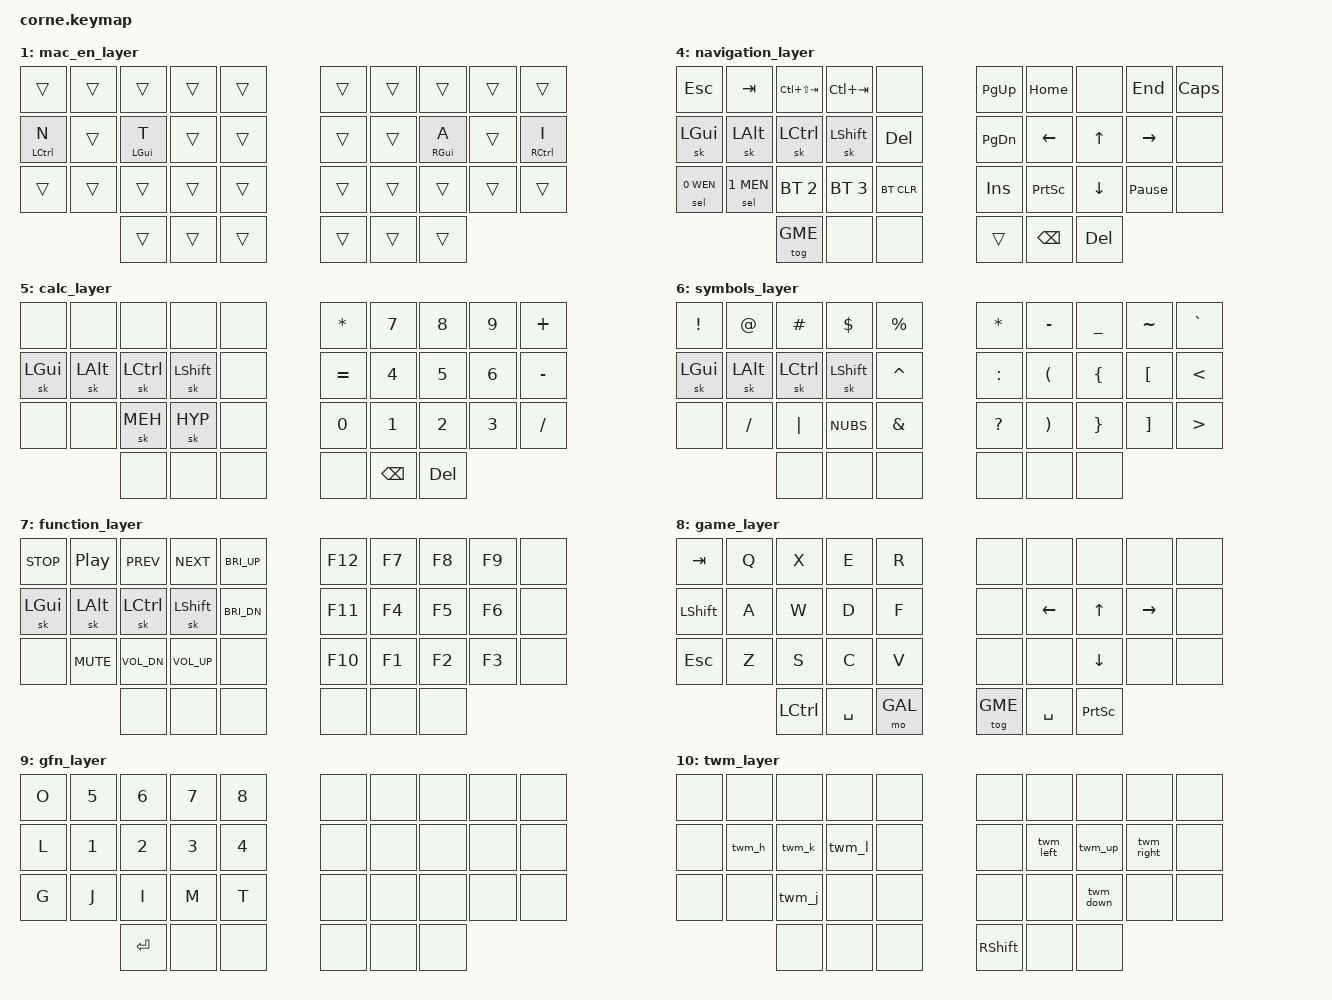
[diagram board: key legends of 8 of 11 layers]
/*
 * Copyright (c) 2020 The ZMK Contributors
 *
 * SPDX-License-Identifier: MIT
 */

#include <behaviors.dtsi>
#include <dt-bindings/zmk/keys.h>
#include <dt-bindings/zmk/bt.h>

#define PRV_TAB   &kp LC(LS(TAB)) 
#define NXT_TAB   &kp LC(TAB)

#define WIN_COPY  LC(C)
#define WIN_PASTE LC(V)
#define WIN_CUT   LC(X)
#define WIN_UNDO  LC(Z)
#define WIN_LANG  LG(SPACE)
#define MAC_COPY  LG(C)
#define MAC_PASTE LG(V)
#define MAC_CUT   LG(X)
#define MAC_UNDO  LG(Z)
#define MAC_LANG  LC(SPACE)

#define KEYS_L 0 1 2 3 4 10 11 12 13 14 20 21 22 23 24 // Left-hand keys
#define KEYS_R 5 6 7 8 9 15 16 17 18 19 25 26 27 28 29 // Right-hand keys
#define THUMBS 30 31 32 33 34 35                       // Thumb keys

// Win modifiers
#define HML(k1, k2, k3, k4)  &hml LGUI  k1 &hml LALT  k2 &hml LCTRL k3 &hml LSHFT k4
#define HMR(k1, k2, k3, k4)  &hmr RSHFT k1 &hmr RCTRL k2 &hmr RALT  k3 &hmr RGUI  k4
// Mac modifiers
#define HMLM(k1, k2, k3, k4) &hml LCTRL k1 &hml LALT  k2 &hml LGUI  k3 &hml LSHFT k4
#define HMRM(k1, k2, k3, k4) &hmr RSHFT k1 &hmr RGUI  k2 &hmr RALT  k3 &hmr RCTRL k4
// Hyper key
#define HYP LS(LC(LA(LGUI)))
// Meh key
#define MEH LS(LC(LALT))

#define COMBO_RU_HS  3  13
#define COMBO_RU_SH  6  16
#define COMBO_RU_YE  16 26
#define COMBO_RU_YO  7  17
#define COMBO_RU_EF  17 27

#define COMBO_COPY  12 22
#define COMBO_PASTE 13 23
#define COMBO_CUT   11 21
#define COMBO_UNDO  14 24
#define COMBO_LANG   2 12

#define WEN 0  // Win EN
#define MEN 1  // Mac EN
#define WRU 2  // Win RU
#define MRU 3  // Mac RU
#define NAV 4  // Navigation
#define CLC 5  // Calculator
#define SYM 6  // Symbols
#define FUN 7  // Functions
#define GME 8  // Game
#define GAL 9  // Game Alt
#define TWM 10 // Tiling Window Manager

#define COMBO_TIMEOUT 50
#define COMBO_IDLE 75
#define QUICK_TAP 150

// Macro-generator for russian letter key combos
#define RU_COMBO(NAME, KEYPOS, BIND) \
    combo_ru_##NAME { \
        timeout-ms = <COMBO_TIMEOUT>; \
        key-positions = <KEYPOS>; \
        bindings = <&kp BIND>; \
        layers = <WRU MRU>; \
	    require-prior-idle-ms = <COMBO_IDLE>; \
    };

// Macro-generator for basic OS combos
#define OS_COMBO(NAME, KEYPOS, WIN_BIND, MAC_BIND) \
    combo_##NAME##_win { \
        timeout-ms = <COMBO_TIMEOUT>; \
        key-positions = <KEYPOS>; \
        bindings = <&kp WIN_BIND>; \
        layers = <WEN WRU>; \
	    require-prior-idle-ms = <COMBO_IDLE>; \
    }; \
    combo_##NAME##_mac { \
        timeout-ms = <COMBO_TIMEOUT>; \
        key-positions = <KEYPOS>; \
        bindings = <&kp MAC_BIND>; \
        layers = <MEN MRU>; \
	    require-prior-idle-ms = <COMBO_IDLE>; \
    };

// Macro-generator for TWM layer
#define TWM_MORPH(NAME, KEY) \
    twm_##NAME: twm_##NAME { \
        compatible = "zmk,behavior-mod-morph"; \
        #binding-cells = <0>; \
        bindings = <&kp LS(LC(LA(KEY)))>, <&kp LS(LC(LA(LG(KEY))))>; \
        mods = <(MOD_RSFT)>; \
    };

&sk {
  quick-release;
};

/*            KEY POSITIONS
  ╭────────────────╮ ╭────────────────╮
  │ 0  1  2  3  4  │ │ 5  6  7  8  9  │
  │ 10 11 12 13 14 │ │ 15 16 17 18 19 │
  │ 20 21 22 23 24 │ │ 25 26 27 28 29 │
  ╰─────╮ 30 31 32 │ │ 33 34 35 ╭─────╯
        ╰──────────╯ ╰──────────╯ */

/ { chosen { zmk,matrix_transform = &five_column_transform; }; };

/ {
    combos {
        compatible = "zmk,combos";

		RU_COMBO(hs, COMBO_RU_HS, RBKT)  // Ъ
		RU_COMBO(sh, COMBO_RU_SH, O)     // Щ
		RU_COMBO(ye, COMBO_RU_YE, SQT)   // Э
		RU_COMBO(yo, COMBO_RU_YO, GRAVE) // Ё
		RU_COMBO(ef, COMBO_RU_EF, A)     // Ф

		OS_COMBO(copy,  COMBO_COPY,  WIN_COPY,  MAC_COPY)
		OS_COMBO(paste, COMBO_PASTE, WIN_PASTE, MAC_PASTE)
        OS_COMBO(cut,   COMBO_CUT,   WIN_CUT,   MAC_CUT)
        OS_COMBO(undo,  COMBO_UNDO,  WIN_UNDO,  MAC_UNDO)

        // Win - Change language
        combo_win_lang {
            timeout-ms = <COMBO_TIMEOUT>;
            key-positions = <COMBO_LANG>;
            bindings = <&lang WRU WIN_LANG>;
            layers = <WEN WRU>;
            require-prior-idle-ms = <COMBO_IDLE>;
        };

        // Mac - Change language
        combo_mac_lang {
            timeout-ms = <COMBO_TIMEOUT>;
            key-positions = <COMBO_LANG>;
            bindings = <&lang MRU MAC_LANG>;
            layers = <MEN MRU>;
            require-prior-idle-ms = <COMBO_IDLE>;
        };
    };  
};

 / {
  macros  {
    // Switch language and activate layer
    lang: lang {
      compatible = "zmk,behavior-macro-two-param";
      #binding-cells = <2>;
      wait-ms = <40>;
      tap-ms = <40>;
      bindings
        = <&macro_param_1to1>
        , <&macro_tap &tog MACRO_PLACEHOLDER>
        , <&macro_param_2to1>
        , <&macro_tap &kp MACRO_PLACEHOLDER>
        ;
    };
    // Select bluetooth profile and OS layer  
    sel: sel {
      compatible = "zmk,behavior-macro-two-param";
      #binding-cells = <2>;
      wait-ms = <40>;
      tap-ms = <40>;
      bindings
        = <&macro_param_1to1>
        , <&macro_tap &bt BT_SEL MACRO_PLACEHOLDER>
        , <&macro_param_2to1>
        , <&macro_tap &to MACRO_PLACEHOLDER>
        ;
    };
  };
};

/ {
    behaviors {
        hml: home_row_mod_left {
            compatible = "zmk,behavior-hold-tap";
            #binding-cells = <2>;
            flavor = "balanced";
            require-prior-idle-ms = <150>;
            tapping-term-ms = <280>;
            quick-tap-ms = <175>;
            bindings = <&kp>, <&kp>;
            hold-trigger-key-positions = <KEYS_R THUMBS>;
            hold-trigger-on-release;
        };
        hmr: home_row_mod_right {
            compatible = "zmk,behavior-hold-tap";
            #binding-cells = <2>;
            flavor = "balanced";
            require-prior-idle-ms = <150>;
            tapping-term-ms = <280>;
            quick-tap-ms = <175>;
            bindings = <&kp>, <&kp>;
            hold-trigger-key-positions = <KEYS_L THUMBS>;
            hold-trigger-on-release;
        };
        ltr: layer_tap_repeat {
            compatible = "zmk,behavior-hold-tap";
            #binding-cells = <2>;
            flavor = "tap-preferred";
            tapping-term-ms = <200>;
            bindings = <&mo>, <&key_repeat>;
			quick-tap-ms = <QUICK_TAP>;
        };

		TWM_MORPH(h, H)
		TWM_MORPH(j, J)
		TWM_MORPH(k, K)
		TWM_MORPH(l, L)
		TWM_MORPH(left, LEFT)
		TWM_MORPH(down, DOWN)
		TWM_MORPH(up, UP)
		TWM_MORPH(right, RIGHT)
    };
};

/ {        
  keymap {
    compatible = "zmk,keymap";

    //Gallium V2
    win_en_layer {
      bindings = <
        //   ╭──────────┬──────────┬──────────┬──────────┬──────────╮                         ╭──────────┬──────────┬──────────┬──────────┬──────────╮
        //   │  B       │  L       │  D       │  C       │  V       │                         │  J       │  Y       │  O       │  U       │  ,       │
                &kp B      &kp L     &lt TWM D   &kp C      &kp V                                &kp J      &kp Y     &lt TWM O   &kp U     &kp COMMA
        //   ├──────────┼──────────┼──────────┼──────────┼──────────┤                         ├──────────┼──────────┼──────────┼──────────┼──────────┤
        //   │  N       │  R       │  T       │  S       │  G       │                         │  P       │  H       │  A       │  E       │  I       │
                HML (N,    R,         T,         S)         &kp G                                &kp P      HMR(H,     A,         E,         I)
        //   ├──────────┼──────────┼──────────┼──────────┼──────────┤                         ├──────────┼──────────┼──────────┼──────────┼──────────┤
        //   │  X       │  Q       │  M       │  W       │  Z       │                         │  K       │  F       │  '       │  ;       │  .       │
                &kp X      &kp Q      &kp M      &kp W      &kp Z                                &kp K      &kp F      &kp SQT   &kp SEMI    &kp DOT
        //   ╰─────────────────────┴──────────┼──────────┼──────────┼──────────╮   ╭──────────┼──────────┼──────────┼──────────┴──────────┴──────────╯
        //                                    │  Repeat  │  SPACE   │  ENTER   │   │  SHIFT   │  BkSPC   │  DEL     │
                                              &ltr CLC 0  &lt NAV SPACE &kp ENTER  &kp LSHIFT &lt SYM BSPC &lt FUN DEL
        //                                    ╰──────────┴──────────┴──────────╯   ╰──────────┴──────────┴──────────╯
      >;
    };

    mac_en_layer {
      bindings = <
        //   ╭──────────┬──────────┬──────────┬──────────┬──────────╮                         ╭──────────┬──────────┬──────────┬──────────┬──────────╮
        //   │  B       │  L       │  D       │  C       │  V       │                         │  J       │  Y       │  O       │  U       │  ,       │
                &trans     &trans     &trans     &trans     &trans                               &trans     &trans     &trans     &trans     &trans
        //   ├──────────┼──────────┼──────────┼──────────┼──────────┤                         ├──────────┼──────────┼──────────┼──────────┼──────────┤
        //   │  N       │  R       │  T       │  S       │  G       │                         │  P       │  H       │  A       │  E       │  I       │
             &hml LCTRL N  &trans   &hml LGUI T  &trans     &trans                               &trans     &trans   &hmr RGUI A  &trans  &hmr RCTRL I
        //   ├──────────┼──────────┼──────────┼──────────┼──────────┤                         ├──────────┼──────────┼──────────┼──────────┼──────────┤
        //   │  X       │  Q       │  M       │  W       │  Z       │                         │  K       │  F       │  '       │  ;       │  .       │
                &trans     &trans     &trans     &trans     &trans                               &trans     &trans     &trans     &trans     &trans
        //   ╰──────────┴──────────┴──────────┼──────────┼──────────┼──────────╮   ╭──────────┼──────────┼──────────┼──────────┴──────────┴──────────╯
        //                                    │  Repeat  │  SPACE   │  ENTER   │   │  SHIFT   │  BkSPC   │  DEL     │
                                                 &trans     &trans     &trans         &trans     &trans     &trans
        //                                    ╰──────────┴──────────┴──────────╯   ╰──────────┴──────────┴──────────╯
      >;
    };

    win_ru_layer {
      bindings = <
        //   ╭──────────┬──────────┬──────────┬──────────┬──────────╮                         ╭──────────┬──────────┬──────────┬──────────┬──────────╮
        //   │  Ц       │  Й       │  К       │  Ь       │  Ч       │                         │  Ш       │  .       │  И       │  Я       │  Ю       │
                &kp W      &kp Q     &lt TWM R   &kp M      &kp X                                &kp I     &kp FSLH   &lt TWM B   &kp Z      &kp DOT
        //   ├──────────┼──────────┼──────────┼───(Ъ)────┼──────────┤                         ├──────────┼───(Щ)────┼───(Ё)────┼──────────┼──────────┤
        //   │  Т       │  Р       │  Н       │  В       │  М       │                         │  ,       │  С       │  А       │  О       │  Е       │
                HML (N,    H,         Y,         D)         &kp V                               &kp QMARK   HMR(C,     F,         J,         T)
        //   ├──────────┼──────────┼──────────┼──────────┼──────────┤                         ├──────────┼───(Э)────┼───(Ф)────┼──────────┼──────────┤
        //   │  Г       │  Л       │  П       │  Д       │  Б       │                         │  Ж       │  З       │  Ы       │  У       │  Х       │
                &kp U      &kp K      &kp G      &kp L     &kp COMMA                             &kp SEMI   &kp P      &kp S      &kp E      &kp LBKT
        //   ╰──────────┴──────────┴──────────┼──────────┼──────────┼──────────╮   ╭──────────┼──────────┼──────────┼──────────┴──────────┴──────────╯
        //                                    │  Repeat  │  SPACE   │  ENTER   │   │  SHIFT   │  BkSPC   │  DEL     │
                                                 &trans     &trans     &trans         &trans     &trans     &trans
        //                                    ╰──────────┴──────────┴──────────╯   ╰──────────┴──────────┴──────────╯
      >;
    };
    
    mac_ru_layer {
      bindings = <
        //   ╭──────────┬──────────┬──────────┬──────────┬──────────╮                         ╭──────────┬──────────┬──────────┬──────────┬──────────╮
        //   │  Ц       │  Й       │  К       │  Ь       │  Ч       │                         │  Ш       │  .       │  И       │  Я       │  Ю       │
                &kp W      &kp Q     &lt TWM R   &kp M      &kp X                                &kp I     &kp FSLH   &lt TWM B   &kp Z      &kp DOT
        //   ├──────────┼──────────┼──────────┼───(Ъ)────┼──────────┤                         ├──────────┼───(Щ)────┼───(Ё)────┼──────────┼──────────┤
        //   │  Т       │  Р       │  Н       │  В       │  М       │                         │  ,       │  С       │  А       │  О       │  Е       │
                HMLM (N,   H,         Y,         D)         &kp V                               &kp QMARK   HMRM(C,    F,         J,         T)
        //   ├──────────┼──────────┼──────────┼──────────┼──────────┤                         ├──────────┼───(Э)────┼───(Ф)────┼──────────┼──────────┤
        //   │  Г       │  Л       │  П       │  Д       │  Б       │                         │  Ж       │  З       │  Ы       │  У       │  Х       │
                &kp U      &kp K      &kp G      &kp L     &kp COMMA                             &kp SEMI   &kp P      &kp S      &kp E      &kp LBKT
        //   ╰──────────┴──────────┴──────────┼──────────┼──────────┼──────────╮   ╭──────────┼──────────┼──────────┼──────────┴──────────┴──────────╯
        //                                    │  Repeat  │  SPACE   │  ENTER   │   │  SHIFT   │  BkSPC   │  DEL     │
                                                 &trans     &trans     &trans         &trans     &trans     &trans
        //                                    ╰──────────┴──────────┴──────────╯   ╰──────────┴──────────┴──────────╯
      >;
    };

    navigation_layer {
      bindings = <
        //   ╭──────────┬──────────┬──────────┬──────────┬──────────╮                         ╭──────────┬──────────┬──────────┬──────────┬──────────╮
        //   │  ESC     │  TAB     │ PREV TAB │ NEXT TAB │          │                         │  PGUP    │  HOME    │          │  END     │  CAPS    │
                &kp ESC    &kp TAB   PRV_TAB    NXT_TAB     &none                               &kp PG_UP  &kp HOME    &none      &kp END   &kp CAPS
        //   ├──────────┼──────────┼──────────┼──────────┼──────────┤                         ├──────────┼──────────┼──────────┼──────────┼──────────┤
        //   │  GUI     │  ALT     │  CTRL    │  SHIFT   │  DEL     │                         │  PGDOWN  │  ←       │  ↑       │  →       │          │
               &sk LGUI   &sk LALT   &sk LCTRL  &sk LSHFT   &kp DEL                             &kp PG_DN  &kp LEFT    &kp UP    &kp RIGHT   &none
        //   ├──────────┼──────────┼──────────┼──────────┼──────────┤                         ├──────────┼──────────┼──────────┼──────────┼──────────┤
        //   │  BT 0    │  BT 1    │  BT 2    │  BT 3    │ BT CLEAR │                         │  INSERT  │  PTSCRN  │  ↓       │  PAUSE   │          │
           &sel 0 WEN &sel 1 MEN &bt BT_SEL 2 &bt BT_SEL 3 &bt BT_CLR                            &kp INS  &kp PSCRN &kp DOWN &kp PAUSE_BREAK &none
        //   ╰──────────┴──────────┴──────────┼──────────┼──────────┼──────────╮   ╭──────────┼──────────┼──────────┼──────────┴──────────┴──────────╯
        //                                    │  GAME    │  X       │          │   │  SHIFT   │  BkSPC   │  DEL     │
                                                &tog GME    &none     &none           &trans    &kp BSPC    &kp DEL
        //                                    ╰──────────┴──────────┴──────────╯   ╰──────────┴──────────┴──────────╯
      >;
    };                
 
    calc_layer {
      bindings = <
        //   ╭──────────┬──────────┬──────────┬──────────┬──────────╮                         ╭──────────┬──────────┬──────────┬──────────┬──────────╮
        //   │          │          │          │          │          │                         │  *       │  7       │  8       │  9       │  +       │
                &none      &none      &none      &none      &none                               &kp STAR    &kp N7     &kp N8     &kp N9    &kp PLUS
        //   ├──────────┼──────────┼──────────┼──────────┼──────────┤                         ├──────────┼──────────┼──────────┼──────────┼──────────┤
        //   │  GUI     │  ALT     │  CTRL    │  SHIFT   │          │                         │  =       │  4       │  5       │  6       │  -       │
               &sk LGUI   &sk LALT   &sk LCTRL  &sk LSHFT   &none                               &kp EQUAL   &kp N4     &kp N5     &kp N6    &kp MINUS
        //   ├──────────┼──────────┼──────────┼──────────┼──────────┤                         ├──────────┼──────────┼──────────┼──────────┼──────────┤
        //   │          │          │          │          │          │                         │  0       │  1       │  2       │  3       │  /       │
                &none      &none     &sk MEH    &sk HYP     &none                                &kp N0     &kp N1     &kp N2     &kp N3    &kp FSLH
        //   ╰──────────┴──────────┴──────────┼──────────┼──────────┼──────────╮   ╭──────────┼──────────┼──────────┼──────────┴──────────┴──────────╯
        //                                    │  X       │          │          │   │          │  BkSPC   │  DEL     │
                                                 &none      &none      &none          &none     &kp BSPC    &kp DEL
        //                                    ╰──────────┴──────────┴──────────╯   ╰──────────┴──────────┴──────────╯
      >;
    };

    symbols_layer {
      bindings = <
        //   ╭──────────┬──────────┬──────────┬──────────┬──────────╮                         ╭──────────┬──────────┬──────────┬──────────┬──────────╮
        //   │  !       │  @       │  #       │  $       │  %       │                         │  *       │  -       │  _       │  ~       │  `       │
               &kp EXCL    &kp AT    &kp HASH   &kp DLLR   &kp PRCNT                            &kp STAR  &kp MINUS   &kp UNDER  &kp TILDE  &kp GRAVE
        //   ├──────────┼──────────┼──────────┼──────────┼──────────┤                         ├──────────┼──────────┼──────────┼──────────┼──────────┤
        //   │  GUI     │  ALT     │  CTRL    │  SHIFT   │  ^       │                         │  :       │  (       │  {       │  [       │  <       │
               &sk LGUI   &sk LALT   &sk LCTRL  &sk LSHFT  &kp CARET                            &kp COLON  &kp LPAR   &kp LBRC   &kp LBKT    &kp LT
        //   ├──────────┼──────────┼──────────┼──────────┼──────────┤                         ├──────────┼──────────┼──────────┼──────────┼──────────┤
        //   │          │  /       │  |       │  \       │  &       │                         │  ?       │  )       │  }       │  ]       │  >       │
                &none     &kp FSLH   &kp PIPE   &kp NUBS   &kp AMPS                             &kp QMARK  &kp RPAR   &kp RBRC   &kp RBKT    &kp GT
        //   ╰──────────┴──────────┴──────────┼──────────┼──────────┼──────────╮   ╭──────────┼──────────┼──────────┼──────────┴──────────┴──────────╯
        //                                    │          │          │          │   │          │  X       │          │
                                                 &none      &none      &none          &none      &none      &none
        //                                    ╰──────────┴──────────┴──────────╯   ╰──────────┴──────────┴──────────╯
      >;
    };

    function_layer {
      bindings = <
        //   ╭──────────┬──────────┬──────────┬──────────┬──────────╮                         ╭──────────┬──────────┬──────────┬──────────┬──────────╮
        //   │  STOP    │  PLAY    │ PREVIOUS │  NEXT    │ BRIGHTUP │                         │  F12     │  F7      │  F8      │  F9      │          │
              &kp C_STOP  &kp C_PP  &kp C_PREV &kp C_NEXT &kp C_BRI_UP                           &kp F12    &kp F7     &kp F8     &kp F9     &none
        //   ├──────────┼──────────┼──────────┼──────────┼──────────┤                         ├──────────┼──────────┼──────────┼──────────┼──────────┤
        //   │  GUI     │  ALT     │  CTRL    │  SHIFT   │ BRIGHTDN │                         │  F11     │  F4      │  F5      │  F6      │          │
               &sk LGUI   &sk LALT   &sk LCTRL  &sk LSHFT &kp C_BRI_DN                           &kp F11    &kp F4     &kp F5     &kp F6     &none
        //   ├──────────┼──────────┼──────────┼──────────┼──────────┤                         ├──────────┼──────────┼──────────┼──────────┼──────────┤
        //   │          │  MUTE    │ VOL DWN  │  VOL UP  │          │                         │  F10     │  F1      │  F2      │  F3      │          │
                &none    &kp C_MUTE &kp C_VOL_DN &kp C_VOL_UP &none                              &kp F10    &kp F1     &kp F2     &kp F3     &none
        //   ╰──────────┴──────────┴──────────┼──────────┼──────────┼──────────╮   ╭──────────┼──────────┼──────────┼──────────┴──────────┴──────────╯
        //                                    │          │          │          │   │          │          │  X       │
                                                 &none      &none      &none          &none      &none      &none
        //                                    ╰──────────┴──────────┴──────────╯   ╰──────────┴──────────┴──────────╯
      >;
    };

    game_layer {
      bindings = <
        //   ╭──────────┬──────────┬──────────┬──────────┬──────────╮                         ╭──────────┬──────────┬──────────┬──────────┬──────────╮
        //   │  TAB     │  Q       │  X       │  E       │  R       │                         │          │          │          │          │          │
                &kp TAB    &kp Q      &kp X      &kp E      &kp R                                &none      &none      &none      &none      &none
        //   ├──────────┼──────────┼──────────┼──────────┼──────────┤                         ├──────────┼──────────┼──────────┼──────────┼──────────┤
        //   │  SHIFT   │  A       │  W       │  D       │  F       │                         │          │  ←       │  ↑       │  →       │          │
              &kp LSHIFT   &kp A      &kp W      &kp D      &kp F                                &none     &kp LEFT    &kp UP    &kp RIGHT   &none
        //   ├──────────┼──────────┼──────────┼──────────┼──────────┤                         ├──────────┼──────────┼──────────┼──────────┼──────────┤
        //   │  ESC     │  Z       │  S       │  C       │  V       │                         │          │          │  ↓       │          │          │
                &kp ESC    &kp Z      &kp S      &kp C      &kp V                                &none      &none     &kp DOWN    &none      &none
        //   ╰──────────┴──────────┴──────────┼──────────┼──────────┼──────────╮   ╭──────────┼──────────┼──────────┼──────────┴──────────┴──────────╯
        //                                    │  CTRL    │  SPACE   │ GAME FN  │   │  BASE    │  SPACE   │  PTSCRN  │
                                                &kp LCTRL  &kp SPACE  &mo GAL        &tog GME   &kp SPACE  &kp PSCRN
        //                                    ╰──────────┴──────────┴──────────╯   ╰──────────┴──────────┴──────────╯
      >;
    };

    gfn_layer {
      bindings = <
        //   ╭──────────┬──────────┬──────────┬──────────┬──────────╮                         ╭──────────┬──────────┬──────────┬──────────┬──────────╮
        //   │  O       │  5       │  6       │  7       │  8       │                         │          │          │          │          │          │
                &kp O      &kp N5     &kp N6     &kp N7     &kp N8                               &none      &none      &none      &none      &none
        //   ├──────────┼──────────┼──────────┼──────────┼──────────┤                         ├──────────┼──────────┼──────────┼──────────┼──────────┤
        //   │  L       │  1       │  2       │  3       │  4       │                         │          │          │          │          │          │
                &kp L      &kp N1     &kp N2     &kp N3     &kp N4                               &none      &none      &none      &none      &none
        //   ├──────────┼──────────┼──────────┼──────────┼──────────┤                         ├──────────┼──────────┼──────────┼──────────┼──────────┤
        //   │  G       │  J       │  I       │  M       │  T       │                         │          │          │          │          │          │
                &kp G      &kp J      &kp I      &kp M      &kp T                                &none      &none      &none      &none      &none
        //   ╰──────────┴──────────┴──────────┼──────────┼──────────┼──────────╮   ╭──────────┼──────────┼──────────┼──────────┴──────────┴──────────╯
        //                                    │  ENTER   │          │  X       │   │          │          │          │
                                                &kp ENTER   &none      &none          &none      &none      &none
        //                                    ╰──────────┴──────────┴──────────╯   ╰──────────┴──────────┴──────────╯
      >;
    };       

    twm_layer {
      bindings = <
        //   ╭──────────┬──────────┬──────────┬──────────┬──────────╮                         ╭──────────┬──────────┬──────────┬──────────┬──────────╮
        //   │          │          │  X       │          │          │                         │          │          │  X       │          │          │
                &none      &none      &none      &none      &none                                &none      &none      &none      &none      &none
        //   ├──────────┼──────────┼──────────┼──────────┼──────────┤                         ├──────────┼──────────┼──────────┼──────────┼──────────┤
        //   │          │  ← (H)   │  ↑ (K)   │  → (L)   │          │                         │          │  ←       │  ↑       │  →       │          │
                &none      &twm_h     &twm_k     &twm_l     &none                                &none     &twm_left  &twm_up   &twm_right   &none
        //   ├──────────┼──────────┼──────────┼──────────┼──────────┤                         ├──────────┼──────────┼──────────┼──────────┼──────────┤
        //   │          │          │  ↓ (J)   │          │          │                         │          │          │  ↓       │          │          │
                &none      &none      &twm_j     &none      &none                                &none     &none      &twm_down   &none      &none
        //   ╰──────────┴──────────┴──────────┼──────────┼──────────┼──────────╮   ╭──────────┼──────────┼──────────┼──────────┴──────────┴──────────╯
        //                                    │          │          │          │   │  SHIFT   │          │          │
                                                 &none      &none      &none         &kp RSHFT   &none      &none
        //                                    ╰──────────┴──────────┴──────────╯   ╰──────────┴──────────┴──────────╯
      >;
    };                
  };
};
